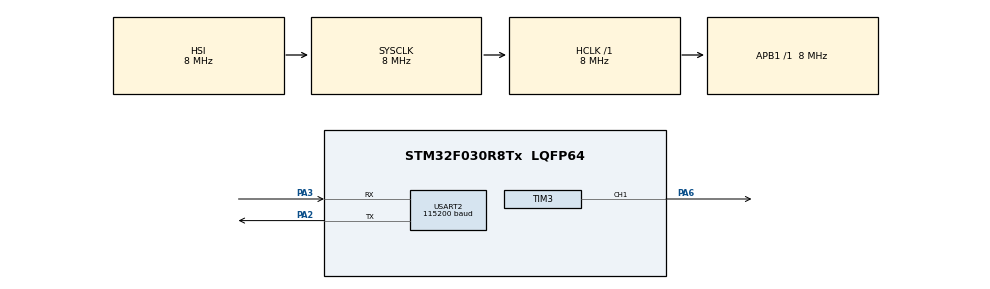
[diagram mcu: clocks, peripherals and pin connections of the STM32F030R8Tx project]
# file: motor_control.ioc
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Mcu.Family=STM32F0
Mcu.Name=STM32F030R8Tx
Mcu.Package=LQFP64
PA2.Mode=Asynchronous
PA2.Signal=USART2_TX
PA3.Mode=Asynchronous
PA3.Signal=USART2_RX
PA6.Signal=S_TIM3_CH1
ProjectManager.HeapSize=0x200
ProjectManager.StackSize=0x400
ProjectManager.TargetToolchain=STM32CubeIDE
RCC.AHBFreq_Value=8000000
RCC.APB1Freq_Value=8000000
RCC.APB1TimFreq_Value=8000000
RCC.HCLKFreq_Value=8000000
RCC.SYSCLKFreq_VALUE=8000000
SH.S_TIM3_CH1.0=TIM3_CH1,PWM Generation1 CH1
TIM3.AutoReloadPreload=TIM_AUTORELOAD_PRELOAD_DISABLE
TIM3.Channel-PWM\ Generation1\ CH1=TIM_CHANNEL_1
TIM3.Channel-PWM\ Generation3\ CH3=TIM_CHANNEL_3
TIM3.Period=255
TIM3.Prescaler=0
TIM3.Pulse-PWM\ Generation1\ CH1=255
USART2.BaudRate=115200
USART2.VirtualMode-Asynchronous=VM_ASYNC
VP_TIM3_VS_ClockSourceINT.Mode=Internal
board=custom

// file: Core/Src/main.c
/* USER CODE BEGIN Header */
/**
  ******************************************************************************
  * @file           : main.c
  * @brief          : Main program body
  ******************************************************************************
  * @attention
  *
  * Copyright (c) 2023 STMicroelectronics.
  * All rights reserved.
  *
  * This software is licensed under terms that can be found in the LICENSE file
  * in the root directory of this software component.
  * If no LICENSE file comes with this software, it is provided AS-IS.
  *
  ******************************************************************************
  */
/* USER CODE END Header */
#include "main.h"

/* USER CODE BEGIN Includes */
#include <stdio.h>
#include "math.h"
/* USER CODE END Includes */

TIM_HandleTypeDef htim3;

UART_HandleTypeDef huart2;

void SystemClock_Config(void);
static void MX_GPIO_Init(void);
static void MX_TIM3_Init(void);
static void MX_USART2_UART_Init(void);

int main(void)
{
  /* USER CODE BEGIN 1 */
  setbuf(stdout, NULL);
  /* USER CODE END 1 */

  /* MCU Configuration--------------------------------------------------------*/

  /* Reset of all peripherals, Initializes the Flash interface and the Systick. */
  HAL_Init();

  /* Configure the system clock */
  SystemClock_Config();

  /* Initialize all configured peripherals */
  MX_GPIO_Init();
  MX_TIM3_Init();
  MX_USART2_UART_Init();
  /* USER CODE BEGIN 2 */
  HAL_TIM_PWM_Start(&htim3, TIM_CHANNEL_1);
  /* USER CODE END 2 */

  /* Infinite loop */
  /* USER CODE BEGIN WHILE */
  while (1)
  {
	double t = HAL_GetTick() / 1000.0;  // ms -> s
	const double gain = 80.0;
	const double offset = 175.0;
	int data = gain * sin(t) + offset;

	__HAL_TIM_SET_COMPARE(&htim3, TIM_CHANNEL_1, data);
	printf("data: %d \n", data);
    /* USER CODE END WHILE */

  }
}

void SystemClock_Config(void)
{
  RCC_OscInitTypeDef RCC_OscInitStruct = {0};
  RCC_ClkInitTypeDef RCC_ClkInitStruct = {0};

  /** Initializes the RCC Oscillators according to the specified parameters
  * in the RCC_OscInitTypeDef structure.
  */
  RCC_OscInitStruct.OscillatorType = RCC_OSCILLATORTYPE_HSI;
  RCC_OscInitStruct.HSIState = RCC_HSI_ON;
  RCC_OscInitStruct.HSICalibrationValue = RCC_HSICALIBRATION_DEFAULT;
  RCC_OscInitStruct.PLL.PLLState = RCC_PLL_NONE;
  if (HAL_RCC_OscConfig(&RCC_OscInitStruct) != HAL_OK)
  {
    Error_Handler();
  }

  /** Initializes the CPU, AHB and APB buses clocks
  */
  RCC_ClkInitStruct.ClockType = RCC_CLOCKTYPE_HCLK|RCC_CLOCKTYPE_SYSCLK
                              |RCC_CLOCKTYPE_PCLK1;
  RCC_ClkInitStruct.SYSCLKSource = RCC_SYSCLKSOURCE_HSI;
  RCC_ClkInitStruct.AHBCLKDivider = RCC_SYSCLK_DIV1;
  RCC_ClkInitStruct.APB1CLKDivider = RCC_HCLK_DIV1;

  if (HAL_RCC_ClockConfig(&RCC_ClkInitStruct, FLASH_LATENCY_0) != HAL_OK)
  {
    Error_Handler();
  }
}

static void MX_TIM3_Init(void)
{

  TIM_ClockConfigTypeDef sClockSourceConfig = {0};
  TIM_MasterConfigTypeDef sMasterConfig = {0};
  TIM_OC_InitTypeDef sConfigOC = {0};

  htim3.Instance = TIM3;
  htim3.Init.Prescaler = 0;
  htim3.Init.CounterMode = TIM_COUNTERMODE_UP;
  htim3.Init.Period = 255;
  htim3.Init.ClockDivision = TIM_CLOCKDIVISION_DIV1;
  htim3.Init.AutoReloadPreload = TIM_AUTORELOAD_PRELOAD_DISABLE;
  if (HAL_TIM_Base_Init(&htim3) != HAL_OK)
  {
    Error_Handler();
  }
  sClockSourceConfig.ClockSource = TIM_CLOCKSOURCE_INTERNAL;
  if (HAL_TIM_ConfigClockSource(&htim3, &sClockSourceConfig) != HAL_OK)
  {
    Error_Handler();
  }
  if (HAL_TIM_PWM_Init(&htim3) != HAL_OK)
  {
    Error_Handler();
  }
  sMasterConfig.MasterOutputTrigger = TIM_TRGO_RESET;
  sMasterConfig.MasterSlaveMode = TIM_MASTERSLAVEMODE_DISABLE;
  if (HAL_TIMEx_MasterConfigSynchronization(&htim3, &sMasterConfig) != HAL_OK)
  {
    Error_Handler();
  }
  sConfigOC.OCMode = TIM_OCMODE_PWM1;
  sConfigOC.Pulse = 255;
  sConfigOC.OCPolarity = TIM_OCPOLARITY_HIGH;
  sConfigOC.OCFastMode = TIM_OCFAST_DISABLE;
  if (HAL_TIM_PWM_ConfigChannel(&htim3, &sConfigOC, TIM_CHANNEL_1) != HAL_OK)
  {
    Error_Handler();
  }
  HAL_TIM_MspPostInit(&htim3);

}

static void MX_USART2_UART_Init(void)
{

  huart2.Instance = USART2;
  huart2.Init.BaudRate = 115200;
  huart2.Init.WordLength = UART_WORDLENGTH_8B;
  huart2.Init.StopBits = UART_STOPBITS_1;
  huart2.Init.Parity = UART_PARITY_NONE;
  huart2.Init.Mode = UART_MODE_TX_RX;
  huart2.Init.HwFlowCtl = UART_HWCONTROL_NONE;
  huart2.Init.OverSampling = UART_OVERSAMPLING_16;
  huart2.Init.OneBitSampling = UART_ONE_BIT_SAMPLE_DISABLE;
  huart2.AdvancedInit.AdvFeatureInit = UART_ADVFEATURE_NO_INIT;
  if (HAL_UART_Init(&huart2) != HAL_OK)
  {
    Error_Handler();
  }

}

static void MX_GPIO_Init(void)
{

  /* GPIO Ports Clock Enable */
  __HAL_RCC_GPIOA_CLK_ENABLE();

}

/* USER CODE BEGIN 4 */
int _write(int file, char *ptr, int len)
{
  HAL_UART_Transmit(&huart2,(uint8_t *)ptr, len, 10);
  return len;
}
/* USER CODE END 4 */

void Error_Handler(void)
{
  __disable_irq();
  while (1)
  {
  }
}
